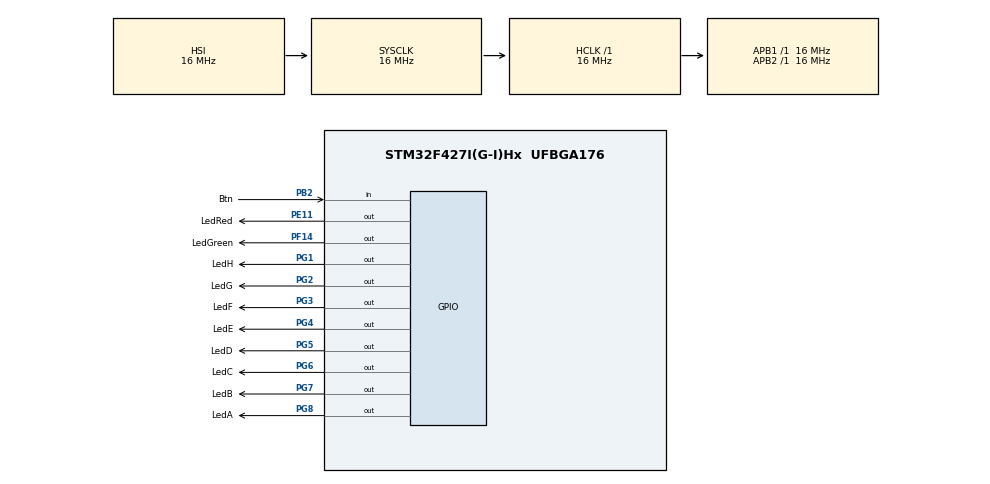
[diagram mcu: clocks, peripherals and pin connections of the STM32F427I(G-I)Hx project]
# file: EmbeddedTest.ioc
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Mcu.Family=STM32F4
RCC.CortexFreq_Value=16000000
PG6.Signal=GPIO_Output
PG7.Signal=GPIO_Output
PG3.Signal=GPIO_Output
PG2.Signal=GPIO_Output
PG1.Signal=GPIO_Output
PE11.GPIO_Label=LedRed
PG8.Signal=GPIO_Output
PG5.Signal=GPIO_Output
PG4.Signal=GPIO_Output
PG6.GPIO_Label=LedC
PF14.GPIO_Label=LedGreen
PG5.GPIO_Label=LedD
ProjectManager.StackSize=0x400
PG8.GPIO_Label=LedA
PB2/BOOT1.Signal=GPIO_Input
ProjectManager.TargetToolchain=SW4STM32
PB2/BOOT1.GPIO_Label=Btn
PE11.Signal=GPIO_Output
RCC.LSE_VALUE=32768
RCC.AHBFreq_Value=16000000
RCC.HSE_VALUE=25000000
board=custom
RCC.VCOOutputFreq_Value=192000000
PG1.GPIO_Label=LedH
RCC.APB2Freq_Value=16000000
PG7.GPIO_Label=LedB
PG4.GPIO_Label=LedE
Mcu.Name=STM32F427I(G-I)Hx
RCC.SYSCLKFreq_VALUE=16000000
Mcu.Package=UFBGA176
ProjectManager.HeapSize=0x200
RCC.HSI_VALUE=16000000
NVIC.PriorityGroup=NVIC_PRIORITYGROUP_4
PF14.Signal=GPIO_Output
PG3.GPIO_Label=LedF
RCC.APB1Freq_Value=16000000
PG2.GPIO_Label=LedG

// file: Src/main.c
/* USER CODE BEGIN Header */
/**
  ******************************************************************************
  * @file           : main.c
  * @brief          : Main program body
  ******************************************************************************
  * @attention
  *
  * <h2><center>&copy; Copyright (c) 2020 STMicroelectronics.
  * All rights reserved.</center></h2>
  *
  * This software component is licensed by ST under BSD 3-Clause license,
  * the "License"; You may not use this file except in compliance with the
  * License. You may obtain a copy of the License at:
  *                        opensource.org/licenses/BSD-3-Clause
  *
  ******************************************************************************
  */
/* USER CODE END Header */
#include "main.h"
#include <stdlib.h>

void SystemClock_Config(void);
static void MX_GPIO_Init(void);

#pragma clang diagnostic push
#pragma ide diagnostic ignored "EndlessLoop"
int main(void)
{

  /* MCU Configuration--------------------------------------------------------*/

  /* Reset of all peripherals, Initializes the Flash interface and the Systick. */
  HAL_Init();

  /* Configure the system clock */
  SystemClock_Config();

  /* Initialize all configured peripherals */
  MX_GPIO_Init();

  /* Infinite loop */
  /* USER CODE BEGIN WHILE */
    uint32_t delays[8];
    int secPressed = 0;
    int started = 0;
    int currIdx = 0;
    int replay = 0;
    int currDelay = 0;
    GPIO_TypeDef *ports[] = {LedA_GPIO_Port, LedB_GPIO_Port, LedC_GPIO_Port, LedD_GPIO_Port, LedE_GPIO_Port,
                             LedF_GPIO_Port, LedG_GPIO_Port, LedH_GPIO_Port};
    uint16_t pins[] = {LedA_Pin, LedB_Pin, LedC_Pin, LedD_Pin, LedE_Pin, LedF_Pin, LedG_Pin, LedH_Pin};
    HAL_Delay(1000);
    HAL_GPIO_WritePin(LedRed_GPIO_Port, LedRed_Pin, GPIO_PIN_SET);
    HAL_GPIO_WritePin(LedGreen_GPIO_Port, LedGreen_Pin, GPIO_PIN_SET);
    for (int i = 0; i < 8; i++) {
        HAL_GPIO_WritePin(ports[i], pins[i], GPIO_PIN_SET);
    }
    while (1) {
    /* USER CODE END WHILE */
        if (started) {
            HAL_GPIO_WritePin(LedGreen_GPIO_Port, LedGreen_Pin, GPIO_PIN_RESET);
        }
        if (HAL_GPIO_ReadPin(Btn_GPIO_Port, Btn_Pin) == GPIO_PIN_SET) {
            secPressed += 50;
            if (secPressed >= 1000) {
                HAL_GPIO_WritePin(LedRed_GPIO_Port, LedRed_Pin, GPIO_PIN_RESET);
                if (secPressed >= 3000 && (secPressed / 100) % 2 == 0) {
                    HAL_GPIO_TogglePin(LedRed_GPIO_Port, LedRed_Pin);
                }
            }
        } else {
            if (started == 0 && secPressed >= 3000) {
                HAL_GPIO_WritePin(LedRed_GPIO_Port, LedRed_Pin, GPIO_PIN_SET);
                while (HAL_GPIO_ReadPin(Btn_GPIO_Port, Btn_Pin) != GPIO_PIN_SET) {
                    int idxToggle = rand() / (RAND_MAX / 8);
                    HAL_GPIO_TogglePin(ports[idxToggle], pins[idxToggle]);
                    HAL_Delay(50);
                    HAL_GPIO_TogglePin(ports[idxToggle], pins[idxToggle]);
                }
                for (int i = 0; i < 8; i++) {
                    HAL_GPIO_WritePin(ports[i], pins[i], GPIO_PIN_SET);
                }
            } else if (secPressed >= 1000) {
                HAL_GPIO_WritePin(LedRed_GPIO_Port, LedRed_Pin, GPIO_PIN_SET);
                if (started == 0) {
                    started = 1;
                    replay = 0;
                    currIdx = 0;
                    currDelay = 0;
                } else {
                    started = 0;
                    replay = 1;
                    HAL_GPIO_WritePin(LedGreen_GPIO_Port, LedGreen_Pin, GPIO_PIN_SET);
                    HAL_GPIO_WritePin(LedRed_GPIO_Port, LedRed_Pin, GPIO_PIN_RESET);
                    for (int i = 0; i < currIdx; i++) {
                        HAL_GPIO_WritePin(ports[i], pins[i], GPIO_PIN_SET);
                    }
                }
            } else if (secPressed > 0) {
                HAL_GPIO_WritePin(LedGreen_GPIO_Port, LedGreen_Pin, GPIO_PIN_SET);
                if (started == 1) {
                    if (currIdx < 8) {
                        delays[currIdx] = currDelay;
                        HAL_GPIO_WritePin(ports[currIdx], pins[currIdx], GPIO_PIN_RESET);
                        currDelay = 0;
                        currIdx += 1;
                    }
                    if (currIdx == 8) {
                        started = 0;
                        replay = 1;
                        HAL_Delay(1000);
                        HAL_GPIO_WritePin(LedGreen_GPIO_Port, LedGreen_Pin, GPIO_PIN_SET);
                        HAL_GPIO_WritePin(LedRed_GPIO_Port, LedRed_Pin, GPIO_PIN_RESET);
                        for (int i = 0; i < currIdx; i++) {
                            HAL_GPIO_WritePin(ports[i], pins[i], GPIO_PIN_SET);
                        }
                    }
                }
            }
            currDelay += 50;
            secPressed = 0;
        }
        HAL_Delay(50);

        if (HAL_GPIO_ReadPin(Btn_GPIO_Port, Btn_Pin) == GPIO_PIN_SET && replay == 1) {
            HAL_GPIO_WritePin(LedGreen_GPIO_Port, LedGreen_Pin, GPIO_PIN_RESET);
            for (int i = 0; i < currIdx; i++) {
                HAL_Delay(delays[i]);
                HAL_GPIO_TogglePin(ports[i], pins[i]);
            }
            HAL_GPIO_WritePin(LedRed_GPIO_Port, LedRed_Pin, GPIO_PIN_SET);
            HAL_Delay(1000);
            for (int i = 0; i < currIdx; i++) {
                HAL_GPIO_WritePin(ports[i], pins[i], GPIO_PIN_SET);
            }
            HAL_GPIO_WritePin(LedGreen_GPIO_Port, LedGreen_Pin, GPIO_PIN_SET);
            currIdx = 0;
            replay = 0;
        }
  }
}
#pragma clang diagnostic pop

void SystemClock_Config(void)
{
  RCC_OscInitTypeDef RCC_OscInitStruct = {0};
  RCC_ClkInitTypeDef RCC_ClkInitStruct = {0};

  /** Configure the main internal regulator output voltage
  */
  __HAL_RCC_PWR_CLK_ENABLE();
  __HAL_PWR_VOLTAGESCALING_CONFIG(PWR_REGULATOR_VOLTAGE_SCALE3);
  /** Initializes the RCC Oscillators according to the specified parameters
  * in the RCC_OscInitTypeDef structure.
  */
  RCC_OscInitStruct.OscillatorType = RCC_OSCILLATORTYPE_HSI;
  RCC_OscInitStruct.HSIState = RCC_HSI_ON;
  RCC_OscInitStruct.HSICalibrationValue = RCC_HSICALIBRATION_DEFAULT;
  RCC_OscInitStruct.PLL.PLLState = RCC_PLL_NONE;
  if (HAL_RCC_OscConfig(&RCC_OscInitStruct) != HAL_OK)
  {
    Error_Handler();
  }
  /** Initializes the CPU, AHB and APB buses clocks
  */
  RCC_ClkInitStruct.ClockType = RCC_CLOCKTYPE_HCLK|RCC_CLOCKTYPE_SYSCLK
                              |RCC_CLOCKTYPE_PCLK1|RCC_CLOCKTYPE_PCLK2;
  RCC_ClkInitStruct.SYSCLKSource = RCC_SYSCLKSOURCE_HSI;
  RCC_ClkInitStruct.AHBCLKDivider = RCC_SYSCLK_DIV1;
  RCC_ClkInitStruct.APB1CLKDivider = RCC_HCLK_DIV1;
  RCC_ClkInitStruct.APB2CLKDivider = RCC_HCLK_DIV1;

  if (HAL_RCC_ClockConfig(&RCC_ClkInitStruct, FLASH_LATENCY_0) != HAL_OK)
  {
    Error_Handler();
  }
}

static void MX_GPIO_Init(void)
{
  GPIO_InitTypeDef GPIO_InitStruct = {0};

  /* GPIO Ports Clock Enable */
  __HAL_RCC_GPIOG_CLK_ENABLE();
  __HAL_RCC_GPIOB_CLK_ENABLE();
  __HAL_RCC_GPIOE_CLK_ENABLE();
  __HAL_RCC_GPIOF_CLK_ENABLE();

  /*Configure GPIO pin Output Level */
  HAL_GPIO_WritePin(GPIOG, LedA_Pin|LedB_Pin|LedC_Pin|LedD_Pin
                          |LedE_Pin|LedF_Pin|LedG_Pin|LedH_Pin, GPIO_PIN_RESET);

  /*Configure GPIO pin Output Level */
  HAL_GPIO_WritePin(LedRed_GPIO_Port, LedRed_Pin, GPIO_PIN_RESET);

  /*Configure GPIO pin Output Level */
  HAL_GPIO_WritePin(LedGreen_GPIO_Port, LedGreen_Pin, GPIO_PIN_RESET);

  /*Configure GPIO pins : LedA_Pin LedB_Pin LedC_Pin LedD_Pin
                           LedE_Pin LedF_Pin LedG_Pin LedH_Pin */
  GPIO_InitStruct.Pin = LedA_Pin|LedB_Pin|LedC_Pin|LedD_Pin
                          |LedE_Pin|LedF_Pin|LedG_Pin|LedH_Pin;
  GPIO_InitStruct.Mode = GPIO_MODE_OUTPUT_PP;
  GPIO_InitStruct.Pull = GPIO_NOPULL;
  GPIO_InitStruct.Speed = GPIO_SPEED_FREQ_LOW;
  HAL_GPIO_Init(GPIOG, &GPIO_InitStruct);

  /*Configure GPIO pin : Btn_Pin */
  GPIO_InitStruct.Pin = Btn_Pin;
  GPIO_InitStruct.Mode = GPIO_MODE_INPUT;
  GPIO_InitStruct.Pull = GPIO_NOPULL;
  HAL_GPIO_Init(Btn_GPIO_Port, &GPIO_InitStruct);

  /*Configure GPIO pin : LedRed_Pin */
  GPIO_InitStruct.Pin = LedRed_Pin;
  GPIO_InitStruct.Mode = GPIO_MODE_OUTPUT_PP;
  GPIO_InitStruct.Pull = GPIO_NOPULL;
  GPIO_InitStruct.Speed = GPIO_SPEED_FREQ_LOW;
  HAL_GPIO_Init(LedRed_GPIO_Port, &GPIO_InitStruct);

  /*Configure GPIO pin : LedGreen_Pin */
  GPIO_InitStruct.Pin = LedGreen_Pin;
  GPIO_InitStruct.Mode = GPIO_MODE_OUTPUT_PP;
  GPIO_InitStruct.Pull = GPIO_NOPULL;
  GPIO_InitStruct.Speed = GPIO_SPEED_FREQ_LOW;
  HAL_GPIO_Init(LedGreen_GPIO_Port, &GPIO_InitStruct);

}

void Error_Handler(void)
{
}

/************************ (C) COPYRIGHT STMicroelectronics *****END OF FILE****/
